AUTOSAR XML (schema 323)
package /Cluster
  can cluster CAN
    physical channel CAN
      frame FRAME_CommandModeControlAPU2: id 0xFF9B41, frame-length=9, can-addressing-mode=STANDARD
        pdu PDU_CommandModeControlAPU2: length=72
          signal Enable_command: start 6, 2 bit, big-endian, data-type=DataType/Enable_command
          signal FaultClear_command: start 4, 2 bit, big-endian, data-type=DataType/FaultClear_command
          signal MasterFollowerMode_command: start 22, 2 bit, big-endian, data-type=DataType/MasterFollowerMode_command
          signal ForceRelayMX1_command: start 38, 2 bit, big-endian, data-type=DataType/ForceRelayMX1_command
          signal ForceRelayMX2_command: start 36, 2 bit, big-endian, data-type=DataType/ForceRelayMX2_command
          signal ForceRelayK1_Precharge_command: start 34, 2 bit, big-endian, data-type=DataType/ForceRelayK1_Precharge_command
          signal ForceRelayRelayK2_DCRun_comand: start 32, 2 bit, big-endian, data-type=DataType/ForceRelayRelayK2_DCRun_comand
          signal InvertHwEnable_command: start 62, 2 bit, big-endian, data-type=DataType/InvertHwEnable_command
          signal EnableUPSMode_command: start 60, 2 bit, big-endian, data-type=DataType/EnableUPSMode_command
          signal EnableSplitPhase_command: start 58, 2 bit, big-endian, data-type=DataType/EnableSplitPhase_command
          signal PhaseRotation_command: start 56, 2 bit, big-endian, data-type=DataType/PhaseRotation_command
      frame FRAME_CommandModeControl: id 0xFFAB41, frame-length=9, can-addressing-mode=STANDARD
        pdu PDU_CommandModeControl: length=72
          signal Enable_command: start 6, 2 bit, big-endian, data-type=DataType/Enable_command
          signal FaultClear_command: start 4, 2 bit, big-endian, data-type=DataType/FaultClear_command
          signal MasterFollowerMode_command: start 22, 2 bit, big-endian, data-type=DataType/MasterFollowerMode_command
          signal ForceRelayMX1_command: start 38, 2 bit, big-endian, data-type=DataType/ForceRelayMX1_command
          signal ForceRelayMX2_command: start 36, 2 bit, big-endian, data-type=DataType/ForceRelayMX2_command
          signal ForceRelayK1_Precharge_command: start 34, 2 bit, big-endian, data-type=DataType/ForceRelayK1_Precharge_command
          signal ForceRelayRelayK2_DCRun_comand: start 32, 2 bit, big-endian, data-type=DataType/ForceRelayRelayK2_DCRun_comand
          signal InvertHwEnable_command: start 62, 2 bit, big-endian, data-type=DataType/InvertHwEnable_command
          signal EnableUPSMode_command: start 60, 2 bit, big-endian, data-type=DataType/EnableUPSMode_command
          signal EnableSplitPhase_command: start 58, 2 bit, big-endian, data-type=DataType/EnableSplitPhase_command
          signal PhaseRotation_command: start 56, 2 bit, big-endian, data-type=DataType/PhaseRotation_command
      frame FRAME_CommandPowerAPU2: id 0xCFF9C41, frame-length=9, can-addressing-mode=STANDARD
        pdu PDU_CommandPowerAPU2: length=72
          signal RealPower_command: start 0, 32 bit, big-endian, data-type=DataType/RealPower_command
          signal ReactivePower_command: start 32, 32 bit, big-endian, data-type=DataType/ReactivePower_command
      frame FRAME_CommandVFAPU2: id 0xCFF9E41, frame-length=8, can-addressing-mode=STANDARD
        pdu PDU_CommandVFAPU2: length=64
          signal Voltage_command: start 0, 16 bit, big-endian, data-type=DataType/Voltage_command
          signal Frequency_command: start 16, 16 bit, big-endian, data-type=DataType/Frequency_command
      frame FRAME_CommandSetNVParam: id 0xCFFAA41, frame-length=9, can-addressing-mode=STANDARD
        pdu PDU_CommandSetNVParam: length=72
          signal CommandSetNVParam_MUX: start 0, 16 bit, big-endian, data-type=CommandSetNVParam_MUX
          signal ThermalOverload: start 22, 2 bit, big-endian, data-type=DataType/ThermalOverload
          signal Dummy: start 16, 16 bit, big-endian, data-type=DataType/Dummy
          signal FreqHi: start 16, 16 bit, big-endian, data-type=DataType/FreqHi
          signal FreqVeryLo: start 16, 16 bit, big-endian, data-type=DataType/FreqVeryLo
          signal K2Open: start 16, 16 bit, big-endian, data-type=K2Open
          signal MX1Open: start 16, 16 bit, big-endian, data-type=MX1Open
          signal MX2Close: start 16, 16 bit, big-endian, data-type=MX2Close
          signal NodeID: start 16, 8 bit, big-endian, data-type=NodeID
          signal VOver120: start 16, 16 bit, big-endian, data-type=DataType/VOver120
          signal VUnder50pct: start 16, 16 bit, big-endian, data-type=DataType/VUnder50pct
          signal SA_Mask: start 24, 8 bit, big-endian, data-type=SA_Mask
          signal Baudrate: start 32, 4 bit, big-endian, data-type=Baudrate
          signal FreqLo: start 32, 16 bit, big-endian, data-type=DataType/FreqLo
          signal K1Open: start 32, 16 bit, big-endian, data-type=K1Open
          signal K2Close: start 32, 16 bit, big-endian, data-type=K2Close
          signal MX1Close: start 32, 16 bit, big-endian, data-type=MX1Close
          signal V50to88pct: start 32, 16 bit, big-endian, data-type=DataType/V50to88pct
          signal FreqHi: start 48, 16 bit, big-endian, data-type=DataType/FreqHi
          signal FreqVeryLo: start 48, 16 bit, big-endian, data-type=DataType/FreqVeryLo
          signal K1Close: start 48, 16 bit, big-endian, data-type=K1Close
          signal MX2Open: start 48, 16 bit, big-endian, data-type=MX2Open
          signal V110to120pct: start 48, 16 bit, big-endian, data-type=DataType/V110to120pct
      frame FRAME_CommandPower: id 0xCFFAC41, frame-length=9, can-addressing-mode=STANDARD
        pdu PDU_CommandPower: length=72
          signal RealPower_command: start 0, 32 bit, big-endian, data-type=DataType/RealPower_command
          signal ReactivePower_command: start 32, 32 bit, big-endian, data-type=DataType/ReactivePower_command
      frame FRAME_CommandVF: id 0xCFFAE41, frame-length=8, can-addressing-mode=STANDARD
        pdu PDU_CommandVF: length=64
          signal Voltage_command: start 0, 16 bit, big-endian, data-type=DataType/Voltage_command
          signal Frequency_command: start 16, 16 bit, big-endian, data-type=DataType/Frequency_command
      frame FRAME_CommandFactoryControl: id 0xCFFAF41, frame-length=9, can-addressing-mode=STANDARD
        pdu PDU_CommandFactoryControl: length=72
          signal WriteSerialNumber: start 6, 2 bit, big-endian, data-type=WriteSerialNumber
          signal FactoryAccess: start 16, 16 bit, big-endian, data-type=FactoryAccess
          signal SerialNumber: start 32, 32 bit, big-endian, data-type=DataType/SerialNumber
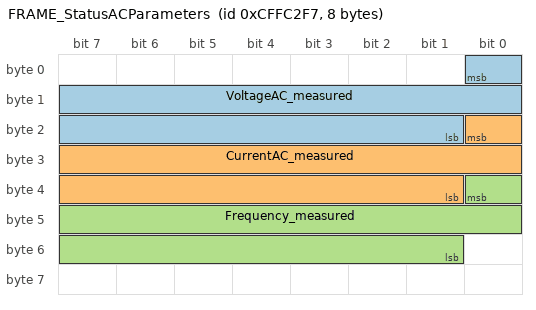
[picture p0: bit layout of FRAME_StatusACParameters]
      frame FRAME_StatusACParameters: id 0xCFFC2F7, frame-length=8, can-addressing-mode=STANDARD
        pdu PDU_StatusACParameters: length=64
          signal VoltageAC_measured: start 0, 16 bit, big-endian, data-type=VoltageAC_measured
          signal CurrentAC_measured: start 16, 16 bit, big-endian, data-type=CurrentAC_measured
          signal Frequency_measured: start 32, 16 bit, big-endian, data-type=Frequency_measured
      frame FRAME_StatusBits: id 0xCFFC3F7, frame-length=8, can-addressing-mode=STANDARD
        pdu PDU_StatusBits: length=64
          signal State_status: start 4, 4 bit, big-endian, data-type=State_status
          signal Enable_echo: start 2, 2 bit, big-endian, data-type=Enable_echo
          signal FaultClr_echo: start 0, 2 bit, big-endian, data-type=FaultClr_echo
          signal HardwareEnable_status: start 14, 2 bit, big-endian, data-type=HardwareEnable_status
          signal PowerAvailAC_status: start 12, 2 bit, big-endian, data-type=PowerAvailAC_status
          signal PowerAvailDC_status: start 10, 2 bit, big-endian, data-type=PowerAvailDC_status
          signal PowerCircuitEnabled_status: start 8, 2 bit, big-endian, data-type=PowerCircuitEnabled_status
          signal MX1Permissive_status: start 22, 2 bit, big-endian, data-type=MX1Permissive_status
          signal MX2Permissive_status: start 20, 2 bit, big-endian, data-type=MX2Permissive_status
          signal K1PrechargePermissive_status: start 18, 2 bit, big-endian, data-type=K1PrechargePermissive_status
          signal K2DCRunPermissive_status: start 16, 2 bit, big-endian, data-type=K2DCRunPermissive_status
          signal MessageValidModeControl_status: start 30, 2 bit, big-endian, data-type=MessageValidModeControl_status
          signal MessageValidPowerCMD_status: start 28, 2 bit, big-endian, data-type=MessageValidPowerCMD_status
          signal MessageValidVF_status: start 26, 2 bit, big-endian, data-type=MessageValidVF_status
          signal CANbus_status: start 24, 2 bit, big-endian, data-type=CANbus_status
          signal EnableUPSMode_echo: start 38, 2 bit, big-endian, data-type=EnableUPSMode_echo
          signal EnableSplitPhase_echo: start 36, 2 bit, big-endian, data-type=EnableSplitPhase_echo
          signal PhaseRotation_status: start 34, 2 bit, big-endian, data-type=PhaseRotation_status
          signal LineVoltageDetected_status: start 32, 2 bit, big-endian, data-type=LineVoltageDetected_status
          signal PhaseRotation_echo: start 46, 2 bit, big-endian, data-type=PhaseRotation_echo
      frame FRAME_StatusFaults: id 0xCFFC8F7, frame-length=8, can-addressing-mode=STANDARD
        pdu PDU_StatusFaults: length=64
          signal GeneralFault_status: start 6, 2 bit, big-endian, data-type=GeneralFault_status
          signal OvercurrentAC_status: start 4, 2 bit, big-endian, data-type=OvercurrentAC_status
          signal LossOfAC_status: start 2, 2 bit, big-endian, data-type=LossOfAC_status
          signal OvercurrentDC_status: start 0, 2 bit, big-endian, data-type=OvercurrentDC_status
          signal OvervoltageDC_status: start 14, 2 bit, big-endian, data-type=OvervoltageDC_status
          signal UndervoltageDC_status: start 12, 2 bit, big-endian, data-type=UndervoltageDC_status
          signal OvertempInternal_status: start 10, 2 bit, big-endian, data-type=OvertempInternal_status
          signal OvertempPowerDevice_status: start 8, 2 bit, big-endian, data-type=OvertempPowerDevice_status
          signal ControlHardwareFail_status: start 20, 4 bit, big-endian, data-type=ControlHardwareFail_status
          signal LossValidControlMessage_status: start 16, 4 bit, big-endian, data-type=LossValidControlMessage_status
          signal EStopShutdown_status: start 30, 2 bit, big-endian, data-type=EStopShutdown_status
          signal IllegalTransition_status: start 28, 2 bit, big-endian, data-type=IllegalTransition_status
          signal InvalidEEHeader_status: start 26, 2 bit, big-endian, data-type=InvalidEEHeader_status
          signal InvalidEESection_status: start 24, 2 bit, big-endian, data-type=InvalidEESection_status
          signal ThermalOverload: start 38, 2 bit, big-endian, data-type=DataType/ThermalOverload
          signal BridgeBFault_status: start 45, 3 bit, big-endian, data-type=BridgeBFault_status
          signal BridgeBVoltageOk_status: start 44, 1 bit, big-endian, data-type=BridgeBVoltageOk_status
          signal BridgeAFault_status: start 61, 3 bit, big-endian, data-type=BridgeAFault_status
          signal BridgeAVoltageOk_status: start 60, 1 bit, big-endian, data-type=BridgeAVoltageOk_status
      frame FRAME_MasterMeasuredPower: id 0xCFFCAF6, frame-length=9, can-addressing-mode=STANDARD
        pdu PDU_MasterMeasuredPower: length=72
          signal RealPower_measured: start 0, 32 bit, big-endian, data-type=DataType/RealPower_measured
          signal ReactivePower_measured: start 32, 32 bit, big-endian, data-type=DataType/ReactivePower_measured
      frame FRAME_StatusMeasuredPower: id 0xCFFCAF7, frame-length=9, can-addressing-mode=STANDARD
        pdu PDU_StatusMeasuredPower: length=72
          signal RealPower_measured: start 0, 32 bit, big-endian, data-type=DataType/RealPower_measured
          signal ReactivePower_measured: start 32, 32 bit, big-endian, data-type=DataType/ReactivePower_measured
      frame FRAME_StatusCommandedPower: id 0x18FFC4F7, frame-length=9, can-addressing-mode=STANDARD
        pdu PDU_StatusCommandedPower: length=72
          signal RealPower_echo: start 0, 32 bit, big-endian, data-type=RealPower_echo
          signal ReactivePower_echo: start 32, 32 bit, big-endian, data-type=ReactivePower_echo
      frame FRAME_StatusCommandVF: id 0x18FFC9F7, frame-length=8, can-addressing-mode=STANDARD
        pdu PDU_StatusCommandVF: length=64
          signal Voltage_echo: start 0, 16 bit, big-endian, data-type=Voltage_echo
          signal Frequency_echo: start 16, 16 bit, big-endian, data-type=Frequency_echo
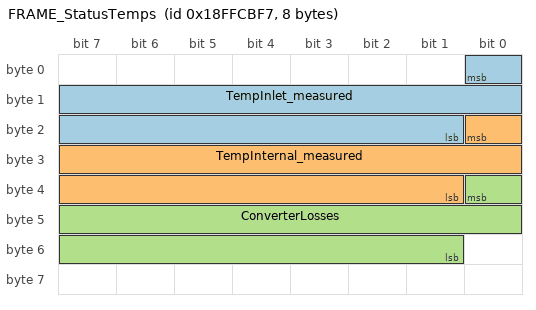
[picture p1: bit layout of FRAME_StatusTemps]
      frame FRAME_StatusTemps: id 0x18FFCBF7, frame-length=8, can-addressing-mode=STANDARD
        pdu PDU_StatusTemps: length=64
          signal TempInlet_measured: start 0, 16 bit, big-endian, data-type=TempInlet_measured
          signal TempInternal_measured: start 16, 16 bit, big-endian, data-type=TempInternal_measured
          signal ConverterLosses: start 32, 16 bit, big-endian, data-type=ConverterLosses
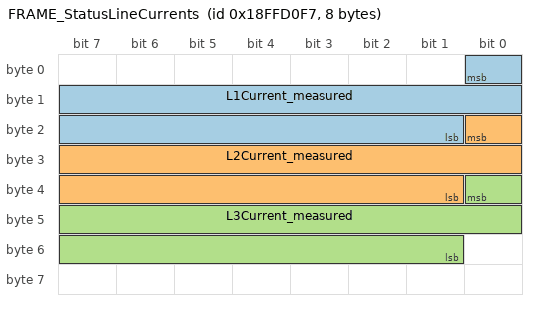
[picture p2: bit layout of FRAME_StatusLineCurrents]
      frame FRAME_StatusLineCurrents: id 0x18FFD0F7, frame-length=8, can-addressing-mode=STANDARD
        pdu PDU_StatusLineCurrents: length=64
          signal L1Current_measured: start 0, 16 bit, big-endian, data-type=L1Current_measured
          signal L2Current_measured: start 16, 16 bit, big-endian, data-type=L2Current_measured
          signal L3Current_measured: start 32, 16 bit, big-endian, data-type=L3Current_measured
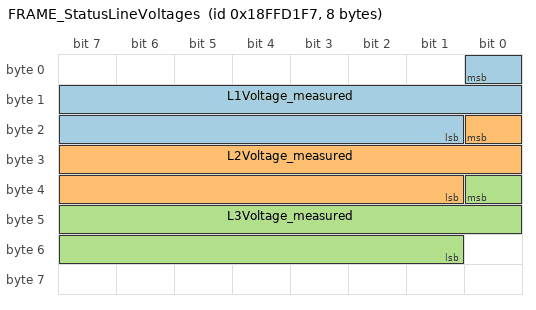
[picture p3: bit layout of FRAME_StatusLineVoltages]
      frame FRAME_StatusLineVoltages: id 0x18FFD1F7, frame-length=8, can-addressing-mode=STANDARD
        pdu PDU_StatusLineVoltages: length=64
          signal L1Voltage_measured: start 0, 16 bit, big-endian, data-type=L1Voltage_measured
          signal L2Voltage_measured: start 16, 16 bit, big-endian, data-type=L2Voltage_measured
          signal L3Voltage_measured: start 32, 16 bit, big-endian, data-type=L3Voltage_measured
      frame FRAME_StatusNVParam: id 0x1CFFA9F7, frame-length=9, can-addressing-mode=STANDARD
        pdu PDU_StatusNVParam: length=72
          signal StatusNVParam_MUX: start 0, 16 bit, big-endian, data-type=StatusNVParam_MUX
          signal StatusThermalOverload: start 22, 2 bit, big-endian, data-type=StatusThermalOverload
          signal Dummy: start 16, 16 bit, big-endian, data-type=DataType/Dummy
          signal FreqHi: start 16, 16 bit, big-endian, data-type=DataType/FreqHi
          signal FreqVeryLo: start 16, 16 bit, big-endian, data-type=DataType/FreqVeryLo
          signal StatusK2Open: start 16, 16 bit, big-endian, data-type=StatusK2Open
          signal StatusMX1Open: start 16, 16 bit, big-endian, data-type=StatusMX1Open
          signal StatusMX2Close: start 16, 16 bit, big-endian, data-type=StatusMX2Close
          signal StatusNodeID: start 16, 8 bit, big-endian, data-type=StatusNodeID
          signal VOver120: start 16, 16 bit, big-endian, data-type=DataType/VOver120
          signal VUnder50pct: start 16, 16 bit, big-endian, data-type=DataType/VUnder50pct
          signal StatusSA_Mask: start 24, 8 bit, big-endian, data-type=StatusSA_Mask
          signal FreqLo: start 32, 16 bit, big-endian, data-type=DataType/FreqLo
          signal StatusBaudrate: start 32, 4 bit, big-endian, data-type=StatusBaudrate
          signal StatusK1Open: start 32, 16 bit, big-endian, data-type=StatusK1Open
          signal StatusK2Close: start 32, 16 bit, big-endian, data-type=StatusK2Close
          signal StatusMX1Close: start 32, 16 bit, big-endian, data-type=StatusMX1Close
          signal V50to88pct: start 32, 16 bit, big-endian, data-type=DataType/V50to88pct
          signal FreqHi: start 48, 16 bit, big-endian, data-type=DataType/FreqHi
          signal FreqVeryLo: start 48, 16 bit, big-endian, data-type=DataType/FreqVeryLo
          signal StatusK1Close: start 48, 16 bit, big-endian, data-type=StatusK1Close
          signal StatusMX2Open: start 48, 16 bit, big-endian, data-type=StatusMX2Open
          signal V110to120pct: start 48, 16 bit, big-endian, data-type=DataType/V110to120pct
      frame FRAME_softwareRev: id 0x1CFFC1F7, frame-length=9, can-addressing-mode=STANDARD
        pdu PDU_softwareRev: length=72
          signal ControlSwRev: start 0, 16 bit, big-endian, data-type=ControlSwRev
          signal InterfaceRev: start 16, 16 bit, big-endian, data-type=InterfaceRev
          signal BuildTime: start 32, 32 bit, big-endian, data-type=BuildTime
      frame FRAME_StatusControlVoltage: id 0x1CFFC5F7, frame-length=9, can-addressing-mode=STANDARD
        pdu PDU_StatusControlVoltage: length=72
          signal v5p0_Supply: start 0, 16 bit, big-endian, data-type=v5p0_Supply
          signal v3p3_Supply: start 16, 16 bit, big-endian, data-type=v3p3_Supply
          signal v24_Supply: start 32, 16 bit, big-endian, data-type=v24_Supply
          signal v15_Supply: start 48, 16 bit, big-endian, data-type=v15_Supply
      frame FRAME_StatusControlVolts2: id 0x1CFFC6F7, frame-length=9, can-addressing-mode=STANDARD
        pdu PDU_StatusControlVolts2: length=72
          signal n15V_Supply: start 0, 16 bit, big-endian, data-type=n15V_Supply
          signal DiodeTemperature: start 32, 16 bit, big-endian, data-type=DiodeTemperature
          signal IGBTTemperature: start 48, 16 bit, big-endian, data-type=IGBTTemperature
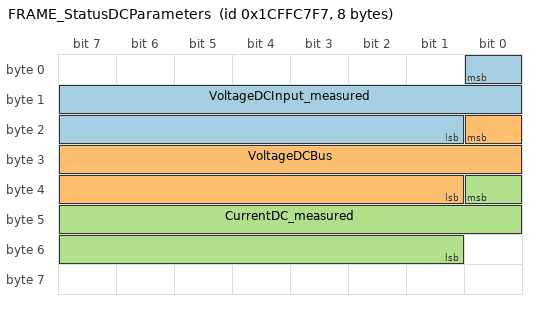
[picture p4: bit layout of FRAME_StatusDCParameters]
      frame FRAME_StatusDCParameters: id 0x1CFFC7F7, frame-length=8, can-addressing-mode=STANDARD
        pdu PDU_StatusDCParameters: length=64
          signal VoltageDCInput_measured: start 0, 16 bit, big-endian, data-type=VoltageDCInput_measured
          signal VoltageDCBus: start 16, 16 bit, big-endian, data-type=VoltageDCBus
          signal CurrentDC_measured: start 32, 16 bit, big-endian, data-type=CurrentDC_measured
      frame FRAME_serialNumber: id 0x1CFFCCF7, frame-length=8, can-addressing-mode=STANDARD
        pdu PDU_serialNumber: length=64
          signal SerialNumber: start 0, 32 bit, big-endian, data-type=DataType/SerialNumber
      frame FRAME_softwareRevHash: id 0x1CFFCDF7, frame-length=8, can-addressing-mode=STANDARD
        pdu PDU_softwareRevHash: length=64
          signal Hash: start 0, 28 bit, big-endian, data-type=Hash
package /ISignal
  31 x i signal:
    Enable_command: system-signal=Signal/Enable_command
    FaultClear_command: system-signal=Signal/FaultClear_command
    MasterFollowerMode_command: system-signal=Signal/MasterFollowerMode_command
    ForceRelayMX1_command: system-signal=Signal/ForceRelayMX1_command
    ForceRelayMX2_command: system-signal=Signal/ForceRelayMX2_command
    ForceRelayK1_Precharge_command: system-signal=Signal/ForceRelayK1_Precharge_command
    ForceRelayRelayK2_DCRun_comand: system-signal=Signal/ForceRelayRelayK2_DCRun_comand
    InvertHwEnable_command: system-signal=Signal/InvertHwEnable_command
    EnableUPSMode_command: system-signal=Signal/EnableUPSMode_command
    EnableSplitPhase_command: system-signal=Signal/EnableSplitPhase_command
    PhaseRotation_command: system-signal=Signal/PhaseRotation_command
    RealPower_command: system-signal=Signal/RealPower_command
    ReactivePower_command: system-signal=Signal/ReactivePower_command
    Voltage_command: system-signal=Signal/Voltage_command
    Frequency_command: system-signal=Signal/Frequency_command
    ThermalOverload: system-signal=Signal/ThermalOverload
    Dummy: system-signal=Signal/Dummy
    FreqHi: system-signal=Signal/FreqHi
    FreqVeryLo: system-signal=Signal/FreqVeryLo
    VOver120: system-signal=Signal/VOver120
    VUnder50pct: system-signal=Signal/VUnder50pct
    FreqLo: system-signal=Signal/FreqLo
    V50to88pct: system-signal=Signal/V50to88pct
    FreqHi: system-signal=Signal/FreqHi
    FreqVeryLo: system-signal=Signal/FreqVeryLo
    V110to120pct: system-signal=Signal/V110to120pct
    SerialNumber: system-signal=Signal/SerialNumber
    RealPower_measured: system-signal=Signal/RealPower_measured
    ReactivePower_measured: system-signal=Signal/ReactivePower_measured
    FreqHi: system-signal=Signal/FreqHi
    FreqVeryLo: system-signal=Signal/FreqVeryLo
package /Signal
  31 x system signal:
    Enable_command: data-type=DataType/Enable_command, length=2
    FaultClear_command: data-type=DataType/FaultClear_command, length=2
    MasterFollowerMode_command: data-type=DataType/MasterFollowerMode_command, length=2
    ForceRelayMX1_command: data-type=DataType/ForceRelayMX1_command, length=2
    ForceRelayMX2_command: data-type=DataType/ForceRelayMX2_command, length=2
    ForceRelayK1_Precharge_command: data-type=DataType/ForceRelayK1_Precharge_command, length=2
    ForceRelayRelayK2_DCRun_comand: data-type=DataType/ForceRelayRelayK2_DCRun_comand, length=2
    InvertHwEnable_command: data-type=DataType/InvertHwEnable_command, length=2
    EnableUPSMode_command: data-type=DataType/EnableUPSMode_command, length=2
    EnableSplitPhase_command: data-type=DataType/EnableSplitPhase_command, length=2
    PhaseRotation_command: data-type=DataType/PhaseRotation_command, length=2
    RealPower_command: data-type=DataType/RealPower_command, length=32
    ReactivePower_command: data-type=DataType/ReactivePower_command, length=32
    Voltage_command: data-type=DataType/Voltage_command, length=16
    Frequency_command: data-type=DataType/Frequency_command, length=16
    ThermalOverload: data-type=DataType/ThermalOverload, length=2
    Dummy: data-type=DataType/Dummy, length=16
    FreqHi: data-type=DataType/FreqHi, length=16
    FreqVeryLo: data-type=DataType/FreqVeryLo, length=16
    VOver120: data-type=DataType/VOver120, length=16
    VUnder50pct: data-type=DataType/VUnder50pct, length=16
    FreqLo: data-type=DataType/FreqLo, length=16
    V50to88pct: data-type=DataType/V50to88pct, length=16
    FreqHi: data-type=DataType/FreqHi, length=16
    FreqVeryLo: data-type=DataType/FreqVeryLo, length=16
    V110to120pct: data-type=DataType/V110to120pct, length=16
    SerialNumber: data-type=DataType/SerialNumber, length=32
    RealPower_measured: data-type=DataType/RealPower_measured, length=32
    ReactivePower_measured: data-type=DataType/ReactivePower_measured, length=32
    FreqHi: data-type=DataType/FreqHi, length=16
    FreqVeryLo: data-type=DataType/FreqVeryLo, length=16
package /DataType
  153 x integer type:
    Enable_command: compu {0=Disable, 1=Enable, 2=Error, 3=N/A, phys=raw}
    FaultClear_command: compu {0=Normal, 1=Clear Faults, 2=Error, 3=N/A, phys=raw}
    MasterFollowerMode_command: compu {0=Master, 1=Follower, 2=Error, 3=N/A, phys=raw}
    ForceRelayMX1_command: compu {0=Normal, 1=Force On, 2=Error, 3=N/A, phys=raw}
    ForceRelayMX2_command: compu {0=Normal, 1=Force On, 2=Error, 3=N/A, phys=raw}
    ForceRelayK1_Precharge_command: compu {0=Normal, 1=Force On, 2=Error, 3=N/A, phys=raw}
    ForceRelayRelayK2_DCRun_comand: compu {0=Normal, 1=Force On, 2=Error, 3=N/A, phys=raw}
    InvertHwEnable_command: compu {0=No invert, 1=Invert, 2=Error, 3=N/A, phys=raw}
    EnableUPSMode_command: compu {0=Disable, 1=Enable, 2=Error, 3=N/A, phys=raw}
    EnableSplitPhase_command: compu-method=Semantics/EnableSplitPhase_command
    PhaseRotation_command: compu {0=Negative, 1=Positive, 2=Error, 3=N/A, phys=raw}
    Enable_command: compu {0=Disable, 1=Enable, 2=Error, 3=N/A, phys=raw}
    FaultClear_command: compu {0=Normal, 1=Clear Faults, 2=Error, 3=N/A, phys=raw}
    MasterFollowerMode_command: compu {0=Master, 1=Follower, 2=Error, 3=N/A, phys=raw}
    ForceRelayMX1_command: compu {0=Normal, 1=Force On, 2=Error, 3=N/A, phys=raw}
    ForceRelayMX2_command: compu {0=Normal, 1=Force On, 2=Error, 3=N/A, phys=raw}
    ForceRelayK1_Precharge_command: compu {0=Normal, 1=Force On, 2=Error, 3=N/A, phys=raw}
    ForceRelayRelayK2_DCRun_comand: compu {0=Normal, 1=Force On, 2=Error, 3=N/A, phys=raw}
    InvertHwEnable_command: compu {0=No invert, 1=Invert, 2=Error, 3=N/A, phys=raw}
    EnableUPSMode_command: compu {0=Disable, 1=Enable, 2=Error, 3=N/A, phys=raw}
    EnableSplitPhase_command: compu-method=Semantics/EnableSplitPhase_command
    PhaseRotation_command: compu {0=Negative, 1=Positive, 2=Error, 3=N/A, phys=raw}
    RealPower_command: compu {phys=raw-90000}
    ReactivePower_command: compu {phys=raw-90000}
    Voltage_command: compu {phys=raw*0.1+10}
    Frequency_command: compu {phys=raw*0.1+45}
    CommandSetNVParam_MUX: compu {0=Param0, 1=LVM_ClearingTimes1, 2=LVM_ClearingTimes2, 3=LFM_Limits, 4=LFM_ClearingTimes, 5=J1939_Interface, 6=Fault_Config, 7=ContactorDelays1, 8=ContactorDelays2, 9=ContactorDelays3, phys=raw}
    ThermalOverload: compu {0=Normal, 1=Fault Active, 2=Error, 3=N/A, phys=raw}
    Dummy: compu {phys=raw+5}
    FreqHi: compu {phys=raw+160}
    FreqVeryLo: compu {phys=raw*0.1+40}
    K2Open: compu {phys=raw}
    MX1Open: compu {phys=raw}
    MX2Close: compu {phys=raw}
    NodeID: compu {phys=raw}
    VOver120: compu {phys=raw+1}
    VUnder50pct: compu {phys=raw+1}
    SA_Mask: compu {phys=raw}
    Baudrate: compu {0=125K, 1=250K, 2=500K, 3=1M, phys=raw}
    FreqLo: compu {phys=raw+1}
    K1Open: compu {phys=raw}
    K2Close: compu {phys=raw}
    MX1Close: compu {phys=raw}
    V50to88pct: compu {phys=raw+1}
    FreqHi: compu {phys=raw+160}
    FreqVeryLo: compu {phys=raw*0.1+40}
    K1Close: compu {phys=raw}
    MX2Open: compu {phys=raw}
    V110to120pct: compu {phys=raw+1}
    RealPower_command: compu {phys=raw-90000}
    ReactivePower_command: compu {phys=raw-90000}
    Voltage_command: compu {phys=raw*0.1+10}
    Frequency_command: compu {phys=raw*0.1+45}
    WriteSerialNumber: compu {0=Disable, 1=Enable, 2=Error, 3=N/A, phys=raw}
    FactoryAccess: compu {phys=raw}
    SerialNumber: compu {phys=raw}
    VoltageAC_measured: compu {phys=raw*0.1}
    CurrentAC_measured: compu {phys=raw}
    Frequency_measured: compu {phys=raw*0.1}
    State_status: compu {0=Power On Reset, 1=Ready, 2=Following, 3=Fault, 4=Forming, 5..15=N/A, phys=raw}
    Enable_echo: compu {0=Disable, 1=Enable, 2=Error, 3=N/A, phys=raw}
    FaultClr_echo: compu {0=Normal, 1=Clear Faults, 2=Error, 3=N/A, phys=raw}
    HardwareEnable_status: compu {0=Not Active, 1=Active, 2=Error, 3=N/A, phys=raw}
    PowerAvailAC_status: compu {0=None, 1=Available, 2=Error, 3=N/A, phys=raw}
    PowerAvailDC_status: compu {0=None, 1=Available, 2=Error, 3=N/A, phys=raw}
    PowerCircuitEnabled_status: compu {0=Disabled, 1=Enabled, 2=Error, 3=N/A, phys=raw}
    MX1Permissive_status: compu {0=Open, 1=Closed, 2=Error, 3=N/A, phys=raw}
    MX2Permissive_status: compu {0=Open, 1=Closed, 2=Error, 3=N/A, phys=raw}
    K1PrechargePermissive_status: compu {0=Open, 1=Closed, 2=Error, 3=N/A, phys=raw}
    K2DCRunPermissive_status: compu {0=Open, 1=Closed, 2=Error, 3=N/A, phys=raw}
    MessageValidModeControl_status: compu {0=Invalid, 1=Valid, 2=Error, 3=N/A, phys=raw}
    MessageValidPowerCMD_status: compu {0=Invalid, 1=Valid, 2=Error, 3=N/A, phys=raw}
    MessageValidVF_status: compu {0=Invalid, 1=Valid, 2=Error, 3=N/A, phys=raw}
    CANbus_status: compu {0=Normal, 1=Warning, 3=ErrorPassive, 4=N/A, phys=raw}
    EnableUPSMode_echo: compu {0=Disable, 1=Enable, 2=Error, 3=N/A, phys=raw}
    EnableSplitPhase_echo: compu {0=Normal - Three Phase Mode, 1=Enable Split Phase Mode, 2=Error, 3=N/A, phys=raw}
    PhaseRotation_status: compu {0=Negative, 1=Positive, 2=Error, 3=N/A, phys=raw}
    LineVoltageDetected_status: compu {0=No_Voltage, 1=Voltage_Detected, 2=Error, 3=N/A, phys=raw}
    PhaseRotation_echo: compu {0=Negative, 1=Positive, 2=Error, 3=N/A, phys=raw}
    GeneralFault_status: compu {0=Normal, 1=Fault Active, 2=Error, 3=N/A, phys=raw}
    OvercurrentAC_status: compu {0=Normal, 1=Fault Active, 2=Error, 3=N/A, phys=raw}
    LossOfAC_status: compu {0=Normal, 1=Fault Active, 2=Error, 3=N/A, phys=raw}
    OvercurrentDC_status: compu {0=Normal, 1=Fault Active, 2=Error, 3=N/A, phys=raw}
    OvervoltageDC_status: compu {0=Normal, 1=Fault Active, 2=Error, 3=N/A, phys=raw}
    UndervoltageDC_status: compu {0=Normal, 1=Fault Active, 2=Error, 3=N/A, phys=raw}
    OvertempInternal_status: compu {0=Normal, 1=Fault Active, 2=Error, 3=N/A, phys=raw}
    OvertempPowerDevice_status: compu {0=Normal, 1=Fault Active, 2=Error, 3=N/A, phys=raw}
    ControlHardwareFail_status: compu {0=Normal, 1=Fault Active, 2=Error, 3=N/A, phys=raw}
    LossValidControlMessage_status: compu {0=Normal, 1=Fault Active, 2=Error, 3=N/A, phys=raw}
    EStopShutdown_status: compu {0=Normal, 1=Fault Active, 2=Error, 3=N/A, phys=raw}
    IllegalTransition_status: compu {0=Normal, 1=Fault Active, 2=Error, 3=N/A, phys=raw}
    InvalidEEHeader_status: compu {0=Normal, 1=Fault Active, 2=Error, 3=N/A, phys=raw}
    InvalidEESection_status: compu {0=Normal, 1=Fault Active, 2=Error, 3=N/A, phys=raw}
    ThermalOverload: compu {0=Normal, 1=Fault Active, 2=Error, 3=N/A, phys=raw}
    BridgeBFault_status: compu {0=Normal, 1=FLT_A, 2=N/A, 3=FLT_C, 4=OverVoltage, 5=FLT_B, 6=Overcurrent, 7=5V, phys=raw}
    BridgeBVoltageOk_status: compu {0=Normal, 1=Fault Active, 2=Error, 3=N/A, phys=raw}
    BridgeAFault_status: compu {0=Normal, 1=FLT_A, 2=N/A, 3=FLT_C, 4=OverVoltage, 5=FLT_B, 6=Overcurrent, 7=5V, phys=raw}
    BridgeAVoltageOk_status: compu {0=Normal, 1=Fault Active, 2=Error, 3=N/A, phys=raw}
    RealPower_measured: compu {phys=raw}
    ReactivePower_measured: compu {phys=raw}
    RealPower_measured: compu {phys=raw}
    ReactivePower_measured: compu {phys=raw}
    RealPower_echo: compu {phys=raw}
    ReactivePower_echo: compu {phys=raw}
    Voltage_echo: compu {phys=raw*0.1}
    Frequency_echo: compu {phys=raw*0.1}
    TempInlet_measured: compu {phys=raw*0.1}
    TempInternal_measured: compu {phys=raw*0.1}
    ConverterLosses: compu {phys=raw}
    L{1..3}Current_measured: compu {phys=raw}
    L{1..3}Voltage_measured: compu {phys=raw*0.1}
    StatusNVParam_MUX: compu {0=ActParam0, 1=ActLVM_ClearingTimes1, 2=ActLVM_ClearingTimes2, 3=ActLFM_Limits, 4=ActLFM_ClearingTimes, 5=StatusJ1939_Interface, 6=StatusFault_Config, 7=StatusContactorDelays1, 8=StatusContactorDelays2, 9=StatusContactorDelays3, phys=raw}
    StatusThermalOverload: compu {0=Warning, 1=Fault, 2=Error, 3=N/A, phys=raw}
    Dummy: compu {phys=raw+5}
    FreqHi: compu {phys=raw+160}
    FreqVeryLo: compu {phys=raw*0.1+40}
    StatusK2Open: compu {phys=raw}
    StatusMX1Open: compu {phys=raw}
    StatusMX2Close: compu {phys=raw}
    StatusNodeID: compu {phys=raw}
    VOver120: compu {phys=raw+1}
    VUnder50pct: compu {phys=raw+1}
    StatusSA_Mask: compu {phys=raw}
    FreqLo: compu {phys=raw+1}
    StatusBaudrate: compu {0=125K, 1=250K, 2=500K, 3=1M, phys=raw}
    StatusK1Open: compu {phys=raw}
    StatusK2Close: compu {phys=raw}
    StatusMX1Close: compu {phys=raw}
    V50to88pct: compu {phys=raw+1}
    FreqHi: compu {phys=raw+160}
    FreqVeryLo: compu {phys=raw*0.1+40}
    StatusK1Close: compu {phys=raw}
    StatusMX2Open: compu {phys=raw}
    V110to120pct: compu {phys=raw+1}
    ControlSwRev: compu {phys=raw}
    InterfaceRev: compu {phys=raw}
    BuildTime: compu {phys=raw}
    v5p0_Supply: compu {phys=raw*0.01}
    v3p3_Supply: compu {phys=raw*0.01}
    v24_Supply: compu {phys=raw*0.01}
    v15_Supply: compu {phys=raw*0.01}
    n15V_Supply: compu {phys=raw*0.01}
    DiodeTemperature: compu {phys=raw}
    IGBTTemperature: compu {phys=raw}
    VoltageDCInput_measured: compu {phys=raw}
    VoltageDCBus: compu {phys=raw}
    CurrentDC_measured: compu {phys=raw}
    SerialNumber: compu {phys=raw}
    Hash: compu {phys=raw}
package /DataType/Semantics
  compu method Enable_command: 0=Disable, 1=Enable, 2=Error, 3=N/A, phys=raw
  compu method FaultClear_command: 0=Normal, 1=Clear Faults, 2=Error, 3=N/A, phys=raw
  compu method MasterFollowerMode_command: 0=Master, 1=Follower, 2=Error, 3=N/A, phys=raw
  compu method ForceRelayMX1_command: 0=Normal, 1=Force On, 2=Error, 3=N/A, phys=raw
  compu method ForceRelayMX2_command: 0=Normal, 1=Force On, 2=Error, 3=N/A, phys=raw
  compu method ForceRelayK1_Precharge_command: 0=Normal, 1=Force On, 2=Error, 3=N/A, phys=raw
  compu method ForceRelayRelayK2_DCRun_comand: 0=Normal, 1=Force On, 2=Error, 3=N/A, phys=raw
  compu method InvertHwEnable_command: 0=No invert, 1=Invert, 2=Error, 3=N/A, phys=raw
  compu method EnableUPSMode_command: 0=Disable, 1=Enable, 2=Error, 3=N/A, phys=raw
  compu method EnableSplitPhase_command: 0=Normal - Three Phase Mode, 1=Enable Split Phase Mode, 2=Error, 3=N/A, phys=raw
  compu method PhaseRotation_command: 0=Negative, 1=Positive, 2=Error, 3=N/A, phys=raw
  compu method EnableSplitPhase_command: 0=Normal - Three Phase Mode, 1=Enable Split Phase Mode, 2=Error, 3=N/A, phys=raw
  compu method RealPower_command: phys=raw-90000
  compu method ReactivePower_command: phys=raw-90000
  compu method Voltage_command: phys=raw*0.1+10
  compu method Frequency_command: phys=raw*0.1+45
  compu method ThermalOverload: 0=Warning, 1=Fault, 2=Error, 3=N/A, phys=raw
  compu method Dummy: phys=raw
  compu method FreqHi: phys=raw*0.1+40
  compu method FreqVeryLo: phys=raw+160
  compu method VOver120: phys=raw+1
  compu method VUnder50pct: phys=raw+1
  compu method FreqLo: phys=raw+1
  compu method V50to88pct: phys=raw+1
  compu method FreqHi: phys=raw+160
  compu method FreqVeryLo: phys=raw*0.1+40
  compu method V110to120pct: phys=raw+1
  compu method SerialNumber: phys=raw
  compu method RealPower_measured: phys=raw
  compu method ReactivePower_measured: phys=raw
  compu method FreqHi: phys=raw*0.1+40
  compu method FreqVeryLo: phys=raw+160
package /DataType/Unit
  153 x unit:
    Enable_command
    FaultClear_command
    MasterFollowerMode_command
    ForceRelayMX1_command
    ForceRelayMX2_command
    ForceRelayK1_Precharge_command
    ForceRelayRelayK2_DCRun_comand
    InvertHwEnable_command
    EnableUPSMode_command
    EnableSplitPhase_command
    PhaseRotation_command
    Enable_command
    FaultClear_command
    MasterFollowerMode_command
    ForceRelayMX1_command
    ForceRelayMX2_command
    ForceRelayK1_Precharge_command
    ForceRelayRelayK2_DCRun_comand
    InvertHwEnable_command
    EnableUPSMode_command
    EnableSplitPhase_command
    PhaseRotation_command
    RealPower_command: display-name=W
    ReactivePower_command: display-name=VA
    Voltage_command: display-name=Vrms
    Frequency_command: display-name=Hz
    CommandSetNVParam_MUX
    ThermalOverload
    Dummy
    FreqHi: display-name=Hz
    FreqVeryLo: display-name=ms
    K2Open: display-name=ms
    MX1Open: display-name=ms
    MX2Close: display-name=ms
    NodeID
    VOver120
    VUnder50pct: display-name=ms
    SA_Mask
    Baudrate
    FreqLo: display-name=ms
    K1Open: display-name=ms
    K2Close: display-name=ms
    MX1Close: display-name=ms
    V50to88pct: display-name=ms
    FreqHi: display-name=ms
    FreqVeryLo: display-name=Hz
    K1Close: display-name=ms
    MX2Open: display-name=ms
    V110to120pct: display-name=ms
    RealPower_command: display-name=W
    ReactivePower_command: display-name=VA
    Voltage_command: display-name=Vrms
    Frequency_command: display-name=Hz
    WriteSerialNumber
    FactoryAccess
    SerialNumber
    VoltageAC_measured: display-name=V
    CurrentAC_measured: display-name=A
    Frequency_measured: display-name=Hz
    State_status
    Enable_echo
    FaultClr_echo
    HardwareEnable_status
    PowerAvailAC_status
    PowerAvailDC_status
    PowerCircuitEnabled_status
    MX1Permissive_status
    MX2Permissive_status
    K1PrechargePermissive_status
    K2DCRunPermissive_status
    MessageValidModeControl_status
    MessageValidPowerCMD_status
    MessageValidVF_status
    CANbus_status
    EnableUPSMode_echo
    EnableSplitPhase_echo
    PhaseRotation_status
    LineVoltageDetected_status
    PhaseRotation_echo
    GeneralFault_status
    OvercurrentAC_status
    LossOfAC_status
    OvercurrentDC_status
    OvervoltageDC_status
    UndervoltageDC_status
    OvertempInternal_status
    OvertempPowerDevice_status
    ControlHardwareFail_status
    LossValidControlMessage_status
    EStopShutdown_status
    IllegalTransition_status
    InvalidEEHeader_status
    InvalidEESection_status
    ThermalOverload
    BridgeBFault_status
    BridgeBVoltageOk_status
    BridgeAFault_status
    BridgeAVoltageOk_status
    RealPower_measured: display-name=W
    ReactivePower_measured: display-name=VA
    RealPower_measured: display-name=W
    ReactivePower_measured: display-name=VA
    RealPower_echo: display-name=W
    ReactivePower_echo: display-name=VA
    Voltage_echo: display-name=Vrms
    Frequency_echo: display-name=Hz
    TempInlet_measured: display-name=C
    TempInternal_measured: display-name=C
    ConverterLosses: display-name=W
    L{1..3}Current_measured: display-name=A
    L{1..3}Voltage_measured: display-name=Vrms
    StatusNVParam_MUX
    StatusThermalOverload
    Dummy
    FreqHi: display-name=Hz
    FreqVeryLo: display-name=ms
    StatusK2Open: display-name=ms
    StatusMX1Open: display-name=ms
    StatusMX2Close: display-name=ms
    StatusNodeID
    VOver120
    VUnder50pct: display-name=ms
    StatusSA_Mask
    FreqLo: display-name=ms
    StatusBaudrate
    StatusK1Open: display-name=ms
    StatusK2Close: display-name=ms
    StatusMX1Close: display-name=ms
    V50to88pct: display-name=ms
    FreqHi: display-name=ms
    FreqVeryLo: display-name=Hz
    StatusK1Close: display-name=ms
    StatusMX2Open: display-name=ms
    V110to120pct: display-name=ms
    ControlSwRev
    InterfaceRev
    BuildTime
    v5p0_Supply: display-name=V
    v3p3_Supply: display-name=V
    v24_Supply: display-name=V
    v15_Supply: display-name=V
    n15V_Supply: display-name=V
    DiodeTemperature: display-name=C
    IGBTTemperature: display-name=C
    VoltageDCInput_measured: display-name=V
    VoltageDCBus: display-name=V
    CurrentDC_measured: display-name=A
    SerialNumber
    Hash
